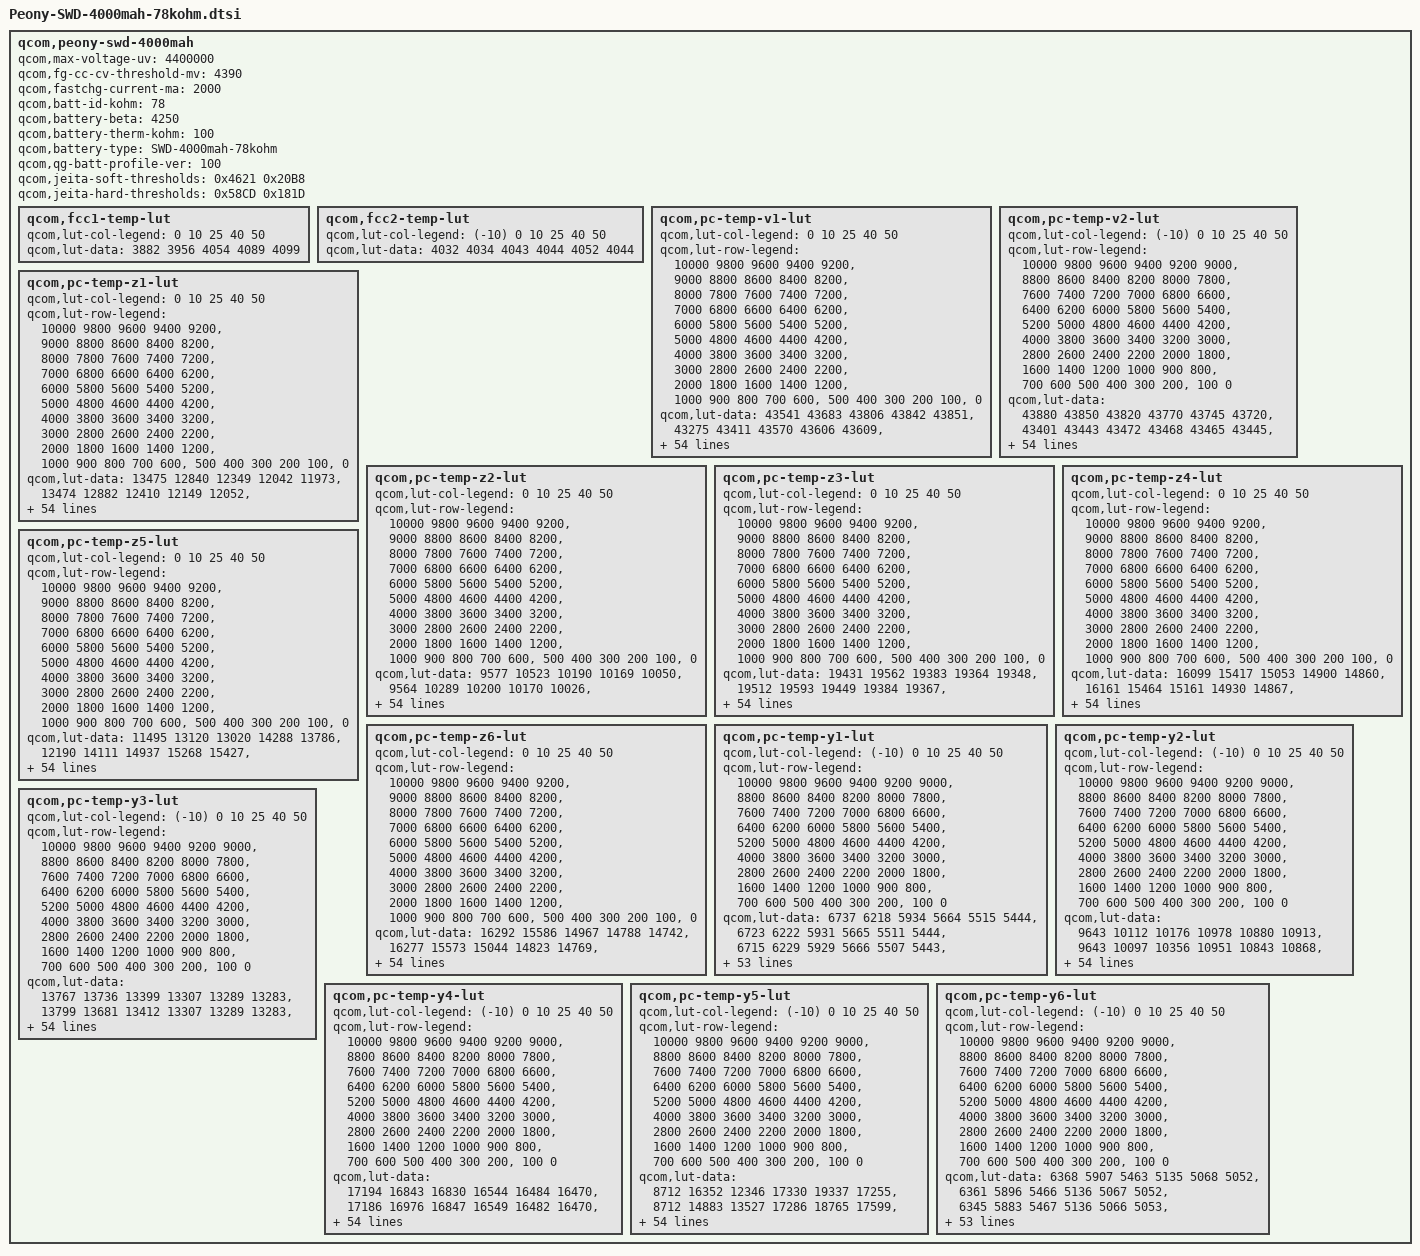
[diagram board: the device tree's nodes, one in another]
/* Copyright (c) 2018, The Linux Foundation. All rights reserved.
 * Copyright (C) 2021 XiaoMi, Inc.
 *
 * This program is free software; you can redistribute it and/or modify
 * it under the terms of the GNU General Public License version 2 and
 * only version 2 as published by the Free Software Foundation.
 *
 * This program is distributed in the hope that it will be useful,
 * but WITHOUT ANY WARRANTY; without even the implied warranty of
 * MERCHANTABILITY or FITNESS FOR A PARTICULAR PURPOSE.  See the
 * GNU General Public License for more details.
 */

qcom,peony-swd-4000mah {
	/* Peony-SWD-4000mah-78kohm_Master_2018.12.27 */
	qcom,max-voltage-uv = <4400000>;
	qcom,fg-cc-cv-threshold-mv = <4390>;
	qcom,fastchg-current-ma = <2000>;
	qcom,batt-id-kohm = <78>;
	qcom,battery-beta = <4250>;
	qcom,battery-therm-kohm = <100>;
	qcom,battery-type =
		"SWD-4000mah-78kohm";
	qcom,qg-batt-profile-ver = <100>;

/*	qcom,jeita-fcc-ranges = <0   50   400000
				 51  100  1200000
				 101 150  1950000
				 151 450  2000000
				 451 550  1000000
				 551 600  0>;
	qcom,jeita-fv-ranges =  <0   50   4400000
				 51  100  4400000
				 101 150  4400000
				 151 450  4400000
				 451 550  4100000
				 551 600  4100000>;*/

	/* COOL = 15 DegC, WARM = 45 DegC */
	qcom,jeita-soft-thresholds = <0x4621 0x20B8>;
	/* COLD = 0 DegC, HOT = 55 DegC */
	qcom,jeita-hard-thresholds = <0x58CD 0x181D>;

	qcom,fcc1-temp-lut {
		qcom,lut-col-legend = <0 10 25 40 50>;
		qcom,lut-data = <3882 3956 4054 4089 4099>;
	};

	qcom,fcc2-temp-lut {
		qcom,lut-col-legend = <(-10) 0 10 25 40 50>;
		qcom,lut-data = <4032 4034 4043 4044 4052 4044>;
	};

	qcom,pc-temp-v1-lut {
		qcom,lut-col-legend = <0 10 25 40 50>;
		qcom,lut-row-legend = <10000 9800 9600 9400 9200>,
			<9000 8800 8600 8400 8200>,
			<8000 7800 7600 7400 7200>,
			<7000 6800 6600 6400 6200>,
			<6000 5800 5600 5400 5200>,
			<5000 4800 4600 4400 4200>,
			<4000 3800 3600 3400 3200>,
			<3000 2800 2600 2400 2200>,
			<2000 1800 1600 1400 1200>,
			<1000 900 800 700 600>,
			<500 400 300 200 100>,
			<0>;
		qcom,lut-data = <43541 43683 43806 43842 43851>,
			<43275 43411 43570 43606 43609>,
			<43017 43151 43319 43369 43380>,
			<42767 42904 43068 43127 43146>,
			<42531 42666 42823 42887 42910>,
			<42307 42434 42582 42647 42670>,
			<42091 42209 42346 42409 42431>,
			<41878 41990 42113 42172 42195>,
			<41669 41772 41886 41936 41962>,
			<41475 41560 41658 41704 41730>,
			<41314 41370 41435 41475 41499>,
			<41148 41210 41236 41255 41274>,
			<40910 41031 41069 41051 41052>,
			<40586 40757 40881 40850 40838>,
			<40298 40426 40595 40622 40629>,
			<40083 40180 40278 40372 40428>,
			<39902 40000 40078 40163 40236>,
			<39765 39853 39947 40008 40056>,
			<39661 39741 39822 39868 39884>,
			<39562 39648 39693 39720 39725>,
			<39452 39520 39554 39571 39576>,
			<39338 39319 39360 39388 39396>,
			<39199 39104 39094 39129 39142>,
			<39007 38911 38883 38893 38902>,
			<38820 38729 38753 38753 38756>,
			<38686 38614 38649 38645 38645>,
			<38577 38552 38557 38541 38538>,
			<38500 38504 38478 38440 38433>,
			<38451 38451 38403 38349 38339>,
			<38412 38402 38327 38271 38259>,
			<38378 38356 38260 38203 38189>,
			<38348 38312 38206 38142 38124>,
			<38320 38272 38161 38088 38065>,
			<38293 38237 38122 38038 38008>,
			<38267 38207 38090 37995 37957>,
			<38240 38176 38058 37953 37907>,
			<38213 38148 38023 37908 37855>,
			<38179 38115 37985 37862 37801>,
			<38123 38060 37933 37803 37735>,
			<38038 37967 37851 37719 37645>,
			<37937 37859 37749 37617 37539>,
			<37800 37738 37631 37502 37421>,
			<37665 37598 37492 37368 37287>,
			<37545 37425 37329 37206 37129>,
			<37395 37276 37180 37069 36995>,
			<37284 37188 37083 36985 36921>,
			<37250 37170 37059 36957 36898>,
			<37219 37156 37038 36943 36880>,
			<37191 37134 37023 36925 36861>,
			<37147 37090 36984 36869 36799>,
			<36944 36871 36748 36601 36515>,
			<36497 36424 36310 36160 36074>,
			<35915 35839 35732 35575 35493>,
			<35123 35041 34936 34772 34695>,
			<33876 33779 33693 33517 33456>,
			<30000 30000 30000 30000 30000>;
	};

	qcom,pc-temp-v2-lut {
		qcom,lut-col-legend = <(-10) 0 10 25 40 50>;
		qcom,lut-row-legend = <10000 9800 9600 9400 9200 9000>,
			<8800 8600 8400 8200 8000 7800>,
			<7600 7400 7200 7000 6800 6600>,
			<6400 6200 6000 5800 5600 5400>,
			<5200 5000 4800 4600 4400 4200>,
			<4000 3800 3600 3400 3200 3000>,
			<2800 2600 2400 2200 2000 1800>,
			<1600 1400 1200 1000 900 800>,
			<700 600 500 400 300 200>,
			<100 0>;
		qcom,lut-data = <43880 43850 43820 43770 43745 43720>,
			<43401 43443 43472 43468 43465 43445>,
			<42991 43077 43154 43183 43197 43181>,
			<42666 42755 42868 42918 42939 42927>,
			<42411 42468 42614 42671 42692 42685>,
			<42152 42218 42366 42429 42450 42446>,
			<41794 42013 42117 42190 42209 42207>,
			<41476 41822 41872 41956 41972 41970>,
			<41393 41583 41619 41726 41740 41737>,
			<41373 41290 41357 41500 41512 41507>,
			<41338 41103 41150 41281 41287 41281>,
			<41194 41046 41020 41075 41065 41059>,
			<40942 40999 40895 40870 40846 40842>,
			<40577 40775 40671 40646 40635 40632>,
			<40009 40190 40326 40407 40428 40428>,
			<39606 39801 40045 40183 40231 40233>,
			<39431 39688 39863 39978 40044 40048>,
			<39291 39599 39704 39793 39866 39871>,
			<39088 39437 39542 39647 39703 39705>,
			<38839 39202 39386 39528 39551 39549>,
			<38644 38962 39210 39379 39377 39375>,
			<38508 38708 38992 39154 39159 39163>,
			<38401 38481 38775 38918 38942 38949>,
			<38321 38339 38594 38730 38756 38761>,
			<38258 38232 38434 38565 38587 38588>,
			<38201 38157 38292 38428 38448 38447>,
			<38148 38105 38157 38317 38335 38335>,
			<38097 38062 38052 38220 38237 38237>,
			<38047 38021 37989 38130 38148 38146>,
			<37998 37983 37945 38048 38069 38064>,
			<37948 37945 37906 37974 37998 37992>,
			<37897 37906 37874 37901 37934 37928>,
			<37845 37867 37842 37842 37873 37866>,
			<37793 37830 37812 37800 37810 37802>,
			<37742 37794 37782 37767 37748 37737>,
			<37686 37753 37746 37729 37681 37659>,
			<37626 37705 37705 37687 37609 37561>,
			<37560 37650 37656 37637 37535 37464>,
			<37486 37585 37593 37569 37461 37387>,
			<37405 37510 37517 37485 37384 37315>,
			<37320 37423 37424 37395 37301 37237>,
			<37227 37317 37306 37295 37209 37150>,
			<37143 37193 37170 37172 37088 37032>,
			<37070 37050 37018 37027 36945 36882>,
			<36999 36930 36897 36900 36832 36782>,
			<36924 36850 36817 36850 36796 36745>,
			<36878 36826 36784 36830 36784 36734>,
			<36834 36797 36762 36816 36768 36718>,
			<36769 36763 36719 36787 36736 36687>,
			<36652 36685 36627 36714 36640 36583>,
			<36411 36471 36416 36471 36313 36229>,
			<36002 36031 35965 35989 35797 35718>,
			<35397 35396 35314 35364 35135 35054>,
			<34515 34492 34421 34520 34259 34176>,
			<33021 33035 33028 33140 32844 32829>,
			<28646 28289 27976 28159 27708 28253>;
	};

	qcom,pc-temp-z1-lut {
		qcom,lut-col-legend = <0 10 25 40 50>;
		qcom,lut-row-legend = <10000 9800 9600 9400 9200>,
			<9000 8800 8600 8400 8200>,
			<8000 7800 7600 7400 7200>,
			<7000 6800 6600 6400 6200>,
			<6000 5800 5600 5400 5200>,
			<5000 4800 4600 4400 4200>,
			<4000 3800 3600 3400 3200>,
			<3000 2800 2600 2400 2200>,
			<2000 1800 1600 1400 1200>,
			<1000 900 800 700 600>,
			<500 400 300 200 100>,
			<0>;
		qcom,lut-data = <13475 12840 12349 12042 11973>,
			<13474 12882 12410 12149 12052>,
			<13506 12909 12422 12154 12061>,
			<13539 12923 12430 12155 12065>,
			<13545 12931 12425 12153 12066>,
			<13522 12928 12413 12147 12065>,
			<13501 12917 12406 12143 12065>,
			<13502 12904 12401 12141 12066>,
			<13511 12894 12399 12139 12068>,
			<13514 12884 12399 12139 12069>,
			<13501 12879 12399 12141 12070>,
			<13479 12878 12399 12142 12070>,
			<13457 12876 12401 12141 12069>,
			<13425 12859 12401 12140 12068>,
			<13396 12831 12389 12136 12069>,
			<13365 12822 12371 12127 12072>,
			<13337 12821 12368 12123 12074>,
			<13332 12820 12371 12125 12071>,
			<13336 12825 12375 12129 12069>,
			<13340 12836 12381 12132 12070>,
			<13340 12844 12388 12136 12072>,
			<13339 12850 12391 12139 12073>,
			<13342 12854 12397 12141 12074>,
			<13367 12855 12402 12143 12075>,
			<13389 12854 12409 12146 12079>,
			<13388 12855 12416 12151 12084>,
			<13378 12858 12418 12155 12088>,
			<13373 12862 12418 12160 12091>,
			<13382 12867 12419 12164 12093>,
			<13393 12872 12422 12169 12097>,
			<13399 12875 12427 12174 12101>,
			<13405 12874 12432 12179 12104>,
			<13409 12874 12436 12184 12107>,
			<13412 12879 12441 12189 12111>,
			<13417 12889 12447 12192 12115>,
			<13425 12900 12452 12196 12120>,
			<13444 12910 12455 12199 12124>,
			<13460 12921 12458 12204 12127>,
			<13462 12928 12462 12209 12131>,
			<13462 12935 12476 12215 12136>,
			<13467 12939 12488 12220 12141>,
			<13502 12933 12489 12225 12147>,
			<13521 12929 12487 12231 12153>,
			<13506 12955 12496 12237 12155>,
			<13533 12969 12504 12245 12158>,
			<13530 12961 12503 12250 12160>,
			<13569 12963 12502 12250 12161>,
			<13543 12961 12510 12248 12162>,
			<13506 12984 12506 12253 12163>,
			<13547 12960 12520 12260 12169>,
			<13537 12977 12522 12266 12178>,
			<13560 12985 12528 12277 12190>,
			<13587 13029 12549 12290 12201>,
			<13611 13039 12576 12311 12219>,
			<13611 13039 12576 12311 12219>,
			<13611 13039 12576 12311 12219>;
	};

	qcom,pc-temp-z2-lut {
		qcom,lut-col-legend = <0 10 25 40 50>;
		qcom,lut-row-legend = <10000 9800 9600 9400 9200>,
			<9000 8800 8600 8400 8200>,
			<8000 7800 7600 7400 7200>,
			<7000 6800 6600 6400 6200>,
			<6000 5800 5600 5400 5200>,
			<5000 4800 4600 4400 4200>,
			<4000 3800 3600 3400 3200>,
			<3000 2800 2600 2400 2200>,
			<2000 1800 1600 1400 1200>,
			<1000 900 800 700 600>,
			<500 400 300 200 100>,
			<0>;
		qcom,lut-data = <9577 10523 10190 10169 10050>,
			<9564 10289 10200 10170 10026>,
			<9701 10159 10222 10168 10025>,
			<9934 10147 10241 10174 9987>,
			<9993 10138 10229 10171 9975>,
			<9980 10126 10201 10157 9973>,
			<9965 10106 10210 10141 9970>,
			<9951 10087 10433 10122 9953>,
			<9937 10072 10630 10099 9927>,
			<9932 10060 10504 10069 9923>,
			<9937 10058 10230 10024 9931>,
			<9941 10064 10154 10003 9941>,
			<9938 10073 10160 10023 9954>,
			<9925 10091 10170 10060 9972>,
			<9916 10115 10192 10100 9984>,
			<9925 10126 10217 10153 9995>,
			<9942 10129 10214 10172 10002>,
			<9963 10133 10178 10103 10006>,
			<9994 10145 10157 10030 10010>,
			<10022 10168 10174 10035 10018>,
			<10042 10192 10210 10067 10033>,
			<10059 10221 10259 10122 10060>,
			<10073 10241 10336 10274 10173>,
			<10084 10239 10371 10393 10277>,
			<10093 10230 10331 10321 10254>,
			<10102 10226 10281 10168 10181>,
			<10111 10226 10282 10143 10156>,
			<10120 10227 10306 10243 10150>,
			<10133 10229 10318 10313 10140>,
			<10146 10232 10320 10259 10096>,
			<10157 10237 10322 10168 10024>,
			<10165 10252 10314 10135 9996>,
			<10174 10267 10295 10121 9979>,
			<10186 10274 10287 10116 9977>,
			<10200 10282 10293 10124 9998>,
			<10213 10288 10304 10142 10032>,
			<10226 10298 10324 10172 10070>,
			<10240 10313 10356 10226 10115>,
			<10255 10327 10380 10267 10155>,
			<10272 10344 10398 10296 10192>,
			<10288 10357 10409 10316 10216>,
			<10302 10364 10405 10324 10212>,
			<10344 10371 10395 10332 10200>,
			<10626 10386 10396 10340 10195>,
			<11070 10505 10420 10319 10188>,
			<11361 10998 10457 10268 10178>,
			<11441 17233 10431 10279 10187>,
			<11704 16563 10415 10274 10188>,
			<11722 12434 10426 10289 10231>,
			<11649 21137 10462 10358 10309>,
			<11112 17245 10476 10258 10163>,
			<10921 24263 10435 10166 10028>,
			<10420 17665 10374 10137 10016>,
			<10119 20353 10374 10116 9962>,
			<10119 20353 10374 10116 9962>,
			<10119 20353 10374 10116 9962>;
	};

	qcom,pc-temp-z3-lut {
		qcom,lut-col-legend = <0 10 25 40 50>;
		qcom,lut-row-legend = <10000 9800 9600 9400 9200>,
			<9000 8800 8600 8400 8200>,
			<8000 7800 7600 7400 7200>,
			<7000 6800 6600 6400 6200>,
			<6000 5800 5600 5400 5200>,
			<5000 4800 4600 4400 4200>,
			<4000 3800 3600 3400 3200>,
			<3000 2800 2600 2400 2200>,
			<2000 1800 1600 1400 1200>,
			<1000 900 800 700 600>,
			<500 400 300 200 100>,
			<0>;
		qcom,lut-data = <19431 19562 19383 19364 19348>,
			<19512 19593 19449 19384 19367>,
			<19628 19612 19476 19403 19381>,
			<19777 19626 19488 19416 19391>,
			<19822 19640 19488 19420 19398>,
			<19825 19642 19487 19421 19403>,
			<19825 19637 19488 19422 19406>,
			<19826 19632 19498 19423 19406>,
			<19828 19630 19507 19424 19405>,
			<19827 19629 19501 19423 19404>,
			<19799 19624 19487 19416 19403>,
			<19765 19607 19475 19411 19400>,
			<19772 19593 19463 19407 19399>,
			<19816 19597 19456 19405 19397>,
			<19842 19606 19461 19406 19394>,
			<19829 19608 19469 19412 19389>,
			<19801 19599 19469 19414 19386>,
			<19772 19585 19458 19404 19382>,
			<19734 19569 19447 19390 19378>,
			<19710 19550 19439 19382 19373>,
			<19705 19546 19432 19376 19367>,
			<19704 19562 19435 19376 19365>,
			<19706 19576 19449 19390 19375>,
			<19720 19576 19456 19402 19385>,
			<19734 19575 19447 19394 19384>,
			<19733 19572 19435 19377 19382>,
			<19728 19567 19437 19378 19384>,
			<19722 19562 19448 19413 19407>,
			<19716 19562 19460 19437 19425>,
			<19710 19563 19471 19434 19421>,
			<19702 19563 19479 19427 19410>,
			<19694 19564 19478 19421 19402>,
			<19686 19564 19471 19413 19395>,
			<19680 19563 19464 19406 19388>,
			<19673 19558 19456 19399 19380>,
			<19667 19554 19450 19393 19372>,
			<19660 19550 19445 19388 19368>,
			<19654 19545 19441 19384 19365>,
			<19648 19541 19438 19382 19364>,
			<19641 19537 19434 19381 19365>,
			<19635 19532 19431 19381 19366>,
			<19631 19526 19428 19381 19368>,
			<19601 19519 19425 19381 19370>,
			<19299 19513 19421 19382 19371>,
			<19259 19487 19411 19378 19370>,
			<19258 19457 19401 19362 19359>,
			<19258 19358 19393 19361 19348>,
			<19258 19259 19393 19349 19342>,
			<19258 19259 19384 19346 19337>,
			<19258 19256 19375 19342 19328>,
			<19258 19257 19377 19367 19359>,
			<19259 19256 19388 19368 19358>,
			<19260 19258 19373 19367 19358>,
			<19261 19256 19366 19370 19361>,
			<19261 19256 19366 19370 19361>,
			<19261 19256 19366 19370 19361>;
	};

	qcom,pc-temp-z4-lut {
		qcom,lut-col-legend = <0 10 25 40 50>;
		qcom,lut-row-legend = <10000 9800 9600 9400 9200>,
			<9000 8800 8600 8400 8200>,
			<8000 7800 7600 7400 7200>,
			<7000 6800 6600 6400 6200>,
			<6000 5800 5600 5400 5200>,
			<5000 4800 4600 4400 4200>,
			<4000 3800 3600 3400 3200>,
			<3000 2800 2600 2400 2200>,
			<2000 1800 1600 1400 1200>,
			<1000 900 800 700 600>,
			<500 400 300 200 100>,
			<0>;
		qcom,lut-data = <16099 15417 15053 14900 14860>,
			<16161 15464 15161 14930 14867>,
			<16010 15449 15104 14926 14876>,
			<15698 15341 15028 14891 14855>,
			<15483 15180 14972 14861 14835>,
			<15346 15074 14921 14834 14814>,
			<15237 15003 14873 14809 14794>,
			<15149 14948 14816 14786 14777>,
			<15076 14905 14777 14767 14761>,
			<15017 14870 14769 14755 14748>,
			<14966 14836 14769 14746 14736>,
			<14928 14800 14762 14738 14727>,
			<14908 14779 14742 14727 14721>,
			<14895 14786 14729 14719 14716>,
			<14886 14801 14747 14720 14712>,
			<14880 14805 14777 14728 14709>,
			<14873 14795 14775 14731 14706>,
			<14861 14779 14738 14715 14701>,
			<14836 14757 14711 14696 14695>,
			<14810 14731 14707 14692 14690>,
			<14786 14725 14705 14690 14686>,
			<14763 14753 14722 14695 14688>,
			<14760 14794 14799 14756 14750>,
			<14797 14840 14848 14815 14809>,
			<14843 14892 14859 14826 14809>,
			<14869 14908 14865 14831 14801>,
			<14890 14891 14858 14825 14786>,
			<14897 14867 14826 14775 14749>,
			<14884 14848 14799 14734 14720>,
			<14865 14829 14779 14727 14714>,
			<14848 14814 14765 14723 14711>,
			<14831 14801 14762 14720 14708>,
			<14816 14790 14761 14718 14704>,
			<14802 14782 14759 14717 14702>,
			<14790 14775 14756 14716 14702>,
			<14778 14769 14754 14716 14703>,
			<14766 14762 14752 14716 14703>,
			<14757 14756 14750 14715 14703>,
			<14753 14756 14749 14715 14704>,
			<14750 14757 14749 14718 14708>,
			<14747 14758 14748 14722 14713>,
			<14740 14748 14741 14716 14709>,
			<14758 14734 14728 14704 14700>,
			<15036 14725 14720 14703 14701>,
			<14999 14700 14700 14695 14695>,
			<14966 14689 14676 14673 14668>,
			<14956 14782 14672 14665 14666>,
			<14948 14880 14660 14659 14655>,
			<14943 14870 14655 14641 14636>,
			<14937 14866 14658 14640 14636>,
			<14941 14878 14674 14650 14653>,
			<14964 14888 14671 14658 14665>,
			<14972 14892 14686 14662 14669>,
			<14986 14896 14695 14660 14668>,
			<14986 14896 14695 14660 14668>,
			<14986 14896 14695 14660 14668>;
	};

	qcom,pc-temp-z5-lut {
		qcom,lut-col-legend = <0 10 25 40 50>;
		qcom,lut-row-legend = <10000 9800 9600 9400 9200>,
			<9000 8800 8600 8400 8200>,
			<8000 7800 7600 7400 7200>,
			<7000 6800 6600 6400 6200>,
			<6000 5800 5600 5400 5200>,
			<5000 4800 4600 4400 4200>,
			<4000 3800 3600 3400 3200>,
			<3000 2800 2600 2400 2200>,
			<2000 1800 1600 1400 1200>,
			<1000 900 800 700 600>,
			<500 400 300 200 100>,
			<0>;
		qcom,lut-data = <11495 13120 13020 14288 13786>,
			<12190 14111 14937 15268 15427>,
			<13179 15039 16021 16292 16148>,
			<14384 15959 16790 17248 16928>,
			<15196 16882 17257 17775 17710>,
			<15678 17603 17589 18034 18512>,
			<16153 18123 18250 18322 19177>,
			<17006 18721 20191 18957 19565>,
			<18126 19823 21863 19684 19867>,
			<18545 21119 21946 19966 20329>,
			<18232 21727 21515 20075 21064>,
			<17866 21932 21448 20214 21839>,
			<19334 22218 21618 20602 22623>,
			<25201 24649 21904 21233 23325>,
			<28678 28936 23283 22834 23724>,
			<27584 29933 25139 26493 24031>,
			<25502 27440 25267 27991 24188>,
			<23856 25095 24277 25577 24556>,
			<22203 24784 23706 23019 24944>,
			<21277 24876 25214 22998 25055>,
			<22402 26225 27919 23538 25366>,
			<25625 37300 30184 24383 25738>,
			<30311 47505 32654 26459 26438>,
			<41671 45742 33636 28034 26988>,
			<51254 39333 28193 24758 24553>,
			<50686 34396 21396 18034 18940>,
			<46843 30667 20788 16923 17836>,
			<43538 28317 21536 21298 22643>,
			<41281 28282 22779 25261 26552>,
			<39415 28759 27028 26628 26596>,
			<38010 29512 31676 27572 26262>,
			<36813 31568 33321 28480 26418>,
			<36188 33992 34301 29376 27193>,
			<36080 35534 34592 29859 27646>,
			<36162 36861 34545 29986 27527>,
			<36465 37717 34443 29997 27309>,
			<37251 38347 34260 29884 27142>,
			<38086 38782 33848 29589 26979>,
			<38749 38743 33169 29128 26718>,
			<39344 38319 31278 27787 25903>,
			<39487 37625 29343 26448 25163>,
			<39092 35306 28396 26034 25348>,
			<36661 33400 27669 25802 26031>,
			<14225 33689 26578 26294 26820>,
			<11496 34738 27103 25856 27421>,
			<11532 30642 28586 22972 24585>,
			<11485 22255 25771 23050 20234>,
			<11480 11508 27864 20983 20450>,
			<11465 11452 26094 23902 23981>,
			<11464 11446 22044 22558 21131>,
			<11507 11433 20588 26361 26006>,
			<11418 11366 22138 22357 21084>,
			<11341 11306 17064 20297 19013>,
			<11237 11214 15793 19604 17686>,
			<11237 11214 15793 19604 17686>,
			<11237 11214 15793 19604 17686>;
	};

	qcom,pc-temp-z6-lut {
		qcom,lut-col-legend = <0 10 25 40 50>;
		qcom,lut-row-legend = <10000 9800 9600 9400 9200>,
			<9000 8800 8600 8400 8200>,
			<8000 7800 7600 7400 7200>,
			<7000 6800 6600 6400 6200>,
			<6000 5800 5600 5400 5200>,
			<5000 4800 4600 4400 4200>,
			<4000 3800 3600 3400 3200>,
			<3000 2800 2600 2400 2200>,
			<2000 1800 1600 1400 1200>,
			<1000 900 800 700 600>,
			<500 400 300 200 100>,
			<0>;
		qcom,lut-data = <16292 15586 14967 14788 14742>,
			<16277 15573 15044 14823 14769>,
			<16208 15550 15026 14827 14777>,
			<16078 15488 15000 14821 14775>,
			<15966 15394 14973 14813 14773>,
			<15871 15326 14944 14801 14768>,
			<15788 15274 14920 14789 14761>,
			<15724 15232 14901 14780 14754>,
			<15671 15200 14885 14772 14747>,
			<15620 15173 14874 14764 14741>,
			<15560 15143 14864 14757 14735>,
			<15511 15107 14853 14751 14729>,
			<15490 15084 14836 14744 14725>,
			<15479 15080 14827 14739 14722>,
			<15467 15079 14834 14740 14718>,
			<15445 15076 14846 14744 14715>,
			<15417 15066 14845 14745 14711>,
			<15388 15052 14824 14733 14706>,
			<15355 15037 14809 14718 14701>,
			<15332 15020 14804 14712 14696>,
			<15324 15017 14802 14709 14691>,
			<15319 15039 14812 14711 14692>,
			<15319 15067 14855 14746 14724>,
			<15345 15090 14878 14777 14755>,
			<15374 15113 14878 14777 14755>,
			<15387 15119 14879 14773 14751>,
			<15396 15112 14877 14771 14748>,
			<15399 15102 14871 14769 14746>,
			<15393 15094 14868 14766 14743>,
			<15382 15088 14867 14763 14738>,
			<15373 15083 14866 14758 14732>,
			<15363 15079 14865 14754 14727>,
			<15354 15076 14861 14750 14722>,
			<15347 15073 14858 14746 14718>,
			<15341 15069 14854 14742 14714>,
			<15336 15067 14851 14739 14710>,
			<15332 15066 14849 14737 14708>,
			<15330 15064 14848 14735 14707>,
			<15332 15066 14848 14735 14706>,
			<15336 15070 14848 14737 14709>,
			<15341 15072 14848 14738 14712>,
			<15348 15068 14846 14737 14712>,
			<15350 15065 14842 14733 14710>,
			<15337 15067 14840 14734 14712>,
			<15317 15056 14832 14730 14709>,
			<15305 15044 14820 14713 14692>,
			<15303 15034 14815 14709 14685>,
			<15301 15026 14810 14701 14677>,
			<15299 15024 14804 14692 14667>,
			<15303 15026 14804 14690 14663>,
			<15312 15038 14816 14710 14688>,
			<15333 15051 14825 14717 14696>,
			<15350 15063 14829 14722 14701>,
			<15378 15081 14838 14727 14706>,
			<15378 15081 14838 14727 14706>,
			<15378 15081 14838 14727 14706>;
	};

	qcom,pc-temp-y1-lut {
		qcom,lut-col-legend = <(-10) 0 10 25 40 50>;
		qcom,lut-row-legend = <10000 9800 9600 9400 9200 9000>,
			<8800 8600 8400 8200 8000 7800>,
			<7600 7400 7200 7000 6800 6600>,
			<6400 6200 6000 5800 5600 5400>,
			<5200 5000 4800 4600 4400 4200>,
			<4000 3800 3600 3400 3200 3000>,
			<2800 2600 2400 2200 2000 1800>,
			<1600 1400 1200 1000 900 800>,
			<700 600 500 400 300 200>,
			<100 0>;
		qcom,lut-data = <6737 6218 5934 5664 5515 5444>,
			<6723 6222 5931 5665 5511 5444>,
			<6715 6229 5929 5666 5507 5443>,
			<6710 6235 5928 5666 5503 5442>,
			<6708 6240 5928 5667 5500 5441>,
			<6707 6242 5928 5667 5497 5439>,
			<6719 6247 5936 5667 5495 5438>,
			<6736 6253 5946 5668 5493 5436>,
			<6740 6250 5945 5666 5492 5435>,
			<6747 6242 5938 5661 5490 5434>,
			<6753 6236 5934 5657 5489 5433>,
			<6752 6242 5933 5656 5487 5432>,
			<6749 6250 5933 5655 5486 5432>,
			<6746 6250 5938 5654 5483 5431>,
			<6735 6249 5950 5652 5479 5431>,
			<6732 6251 5956 5651 5477 5431>,
			<6757 6257 5955 5657 5484 5431>,
			<6786 6264 5953 5665 5491 5431>,
			<6782 6266 5954 5664 5491 5431>,
			<6757 6263 5959 5660 5488 5432>,
			<6744 6262 5961 5658 5487 5433>,
			<6740 6268 5960 5663 5488 5435>,
			<6739 6275 5959 5669 5488 5437>,
			<6741 6276 5958 5672 5491 5438>,
			<6748 6276 5961 5676 5497 5440>,
			<6751 6277 5961 5680 5500 5441>,
			<6742 6278 5959 5685 5500 5443>,
			<6733 6278 5957 5690 5501 5445>,
			<6728 6270 5957 5691 5506 5448>,
			<6721 6255 5959 5693 5514 5452>,
			<6720 6250 5960 5695 5519 5456>,
			<6731 6254 5959 5701 5522 5462>,
			<6741 6257 5957 5707 5525 5466>,
			<6746 6259 5956 5711 5528 5468>,
			<6756 6266 5956 5714 5532 5469>,
			<6760 6268 5956 5715 5535 5471>,
			<6749 6261 5960 5716 5538 5473>,
			<6738 6254 5964 5717 5541 5474>,
			<6732 6257 5963 5719 5544 5476>,
			<6720 6265 5961 5721 5547 5477>,
			<6717 6267 5960 5723 5549 5479>,
			<6718 6256 5960 5729 5551 5483>,
			<6726 6255 5962 5737 5554 5486>,
			<6751 6270 5973 5747 5559 5489>,
			<6782 6277 5990 5753 5569 5498>,
			<6797 6304 5998 5756 5575 5499>,
			<6836 6318 5988 5761 5575 5499>,
			<6816 6303 5992 5760 5573 5498>,
			<6850 6305 6020 5755 5572 5498>,
			<6829 6323 6024 5756 5570 5497>,
			<6824 6332 6015 5760 5576 5501>,
			<6864 6337 6039 5772 5586 5509>,
			<6953 6357 6044 5791 5599 5518>,
			<6976 6403 6084 5801 5619 5530>,
			<6976 6403 6084 5801 5619 5530>,
			<6976 6403 6084 5801 5619 5530>;
	};

	qcom,pc-temp-y2-lut {
		qcom,lut-col-legend = <(-10) 0 10 25 40 50>;
		qcom,lut-row-legend = <10000 9800 9600 9400 9200 9000>,
			<8800 8600 8400 8200 8000 7800>,
			<7600 7400 7200 7000 6800 6600>,
			<6400 6200 6000 5800 5600 5400>,
			<5200 5000 4800 4600 4400 4200>,
			<4000 3800 3600 3400 3200 3000>,
			<2800 2600 2400 2200 2000 1800>,
			<1600 1400 1200 1000 900 800>,
			<700 600 500 400 300 200>,
			<100 0>;
		qcom,lut-data = <9643 10112 10176 10978 10880 10913>,
			<9643 10097 10356 10951 10843 10868>,
			<9842 10090 10474 10926 10803 10813>,
			<10047 10090 10544 10903 10765 10758>,
			<10129 10096 10577 10881 10733 10710>,
			<10143 10107 10585 10862 10712 10680>,
			<9966 10208 10534 10844 10698 10662>,
			<9715 10341 10464 10828 10688 10648>,
			<9675 10346 10473 10817 10686 10640>,
			<9675 10277 10556 10809 10692 10635>,
			<9675 10240 10609 10795 10693 10631>,
			<9676 10296 10619 10742 10669 10622>,
			<9677 10402 10626 10686 10642 10610>,
			<9676 10512 10676 10704 10643 10600>,
			<9671 10644 10812 10796 10660 10587>,
			<9668 10796 10903 10866 10678 10583>,
			<9668 11029 10931 10896 10721 10597>,
			<9667 11222 10956 10925 10778 10623>,
			<9667 10978 11028 10991 10825 10658>,
			<9667 10108 11152 11096 10873 10715>,
			<9666 9701 11199 11135 10918 10776>,
			<9666 9690 11192 11125 10968 10859>,
			<9665 9685 11177 11114 10999 10921>,
			<9665 9682 11128 11114 10982 10920>,
			<9664 9681 11010 11116 10939 10897>,
			<9664 9679 10863 11122 10928 10885>,
			<9664 9677 10619 11143 10952 10878>,
			<9664 9674 10440 11171 10984 10873>,
			<9664 9671 10546 11202 11025 10898>,
			<9663 9669 10806 11240 11081 10961>,
			<9663 9668 10862 11249 11114 11014>,
			<9663 9666 10578 11225 11149 11071>,
			<9662 9665 10237 11195 11170 11108>,
			<9662 9664 10009 11178 11173 11098>,
			<9662 9663 9818 11161 11174 11068>,
			<9662 9663 9740 11138 11161 11038>,
			<9662 9662 9708 11100 11119 10996>,
			<9662 9661 9690 11057 11076 10953>,
			<9662 9661 9682 11018 11046 10909>,
			<9661 9661 9677 10978 11020 10870>,
			<9661 9660 9673 10939 11006 10865>,
			<9661 9660 9670 10902 10996 10880>,
			<9661 9660 9667 10850 10966 10877>,
			<9660 9659 9665 10782 10900 10834>,
			<9660 9659 9663 10714 10830 10730>,
			<9659 9659 9663 10740 10795 10661>,
			<9659 9659 9662 10679 10769 10648>,
			<9659 9658 9661 10699 10801 10716>,
			<9658 9658 9660 10677 10830 10736>,
			<9657 9658 9660 10659 10831 10734>,
			<9657 9657 9659 10628 10790 10671>,
			<9656 9656 9658 10562 10721 10616>,
			<9654 9656 9657 10488 10649 10542>,
			<9652 9655 9656 10450 10665 10487>,
			<9652 9655 9656 10450 10665 10487>,
			<9652 9655 9656 10450 10665 10487>;
	};

	qcom,pc-temp-y3-lut {
		qcom,lut-col-legend = <(-10) 0 10 25 40 50>;
		qcom,lut-row-legend = <10000 9800 9600 9400 9200 9000>,
			<8800 8600 8400 8200 8000 7800>,
			<7600 7400 7200 7000 6800 6600>,
			<6400 6200 6000 5800 5600 5400>,
			<5200 5000 4800 4600 4400 4200>,
			<4000 3800 3600 3400 3200 3000>,
			<2800 2600 2400 2200 2000 1800>,
			<1600 1400 1200 1000 900 800>,
			<700 600 500 400 300 200>,
			<100 0>;
		qcom,lut-data = <13767 13736 13399 13307 13289 13283>,
			<13799 13681 13412 13307 13289 13283>,
			<13807 13642 13420 13308 13289 13284>,
			<13796 13618 13423 13309 13289 13284>,
			<13773 13605 13425 13310 13289 13285>,
			<13740 13601 13425 13311 13289 13285>,
			<13682 13616 13418 13312 13289 13286>,
			<13620 13638 13409 13313 13289 13287>,
			<13602 13609 13415 13314 13289 13287>,
			<13594 13472 13447 13316 13292 13288>,
			<13592 13397 13464 13317 13293 13288>,
			<13607 13422 13418 13319 13293 13289>,
			<13626 13455 13361 13320 13292 13290>,
			<13615 13454 13364 13320 13293 13290>,
			<13567 13431 13397 13319 13296 13290>,
			<13543 13414 13412 13319 13297 13291>,
			<13560 13406 13394 13317 13299 13293>,
			<13582 13402 13371 13315 13300 13296>,
			<13583 13405 13365 13315 13300 13296>,
			<13579 13418 13362 13314 13298 13295>,
			<13577 13424 13358 13312 13297 13294>,
			<13576 13417 13348 13309 13294 13292>,
			<13575 13404 13337 13305 13291 13289>,
			<13581 13388 13330 13302 13289 13286>,
			<13602 13367 13326 13299 13286 13282>,
			<13625 13360 13316 13298 13285 13281>,
			<13648 13381 13286 13297 13284 13281>,
			<13673 13411 13261 13297 13284 13281>,
			<13697 13436 13273 13296 13284 13281>,
			<13721 13460 13304 13295 13284 13281>,
			<13747 13486 13315 13295 13284 13281>,
			<13777 13514 13315 13294 13283 13280>,
			<13808 13544 13315 13293 13283 13280>,
			<13839 13578 13322 13294 13283 13280>,
			<13868 13618 13337 13295 13284 13282>,
			<13898 13656 13350 13297 13284 13282>,
			<13929 13695 13359 13298 13285 13281>,
			<13960 13732 13369 13300 13285 13280>,
			<13992 13768 13386 13300 13286 13281>,
			<14024 13802 13410 13300 13287 13283>,
			<14057 13834 13437 13301 13288 13285>,
			<14089 13862 13469 13305 13289 13286>,
			<14129 13892 13510 13306 13289 13286>,
			<14182 13927 13560 13307 13288 13283>,
			<14251 13969 13614 13309 13287 13284>,
			<14273 13973 13602 13311 13292 13288>,
			<14327 14025 13646 13313 13295 13291>,
			<14400 14066 13709 13320 13299 13293>,
			<14474 14132 13758 13325 13301 13295>,
			<14561 14189 13819 13331 13301 13294>,
			<14653 14244 13871 13332 13297 13290>,
			<14793 14318 13937 13333 13299 13292>,
			<15261 14461 14072 13341 13305 13297>,
			<16342 14686 14250 13356 13316 13308>,
			<16342 14686 14250 13356 13316 13308>,
			<16342 14686 14250 13356 13316 13308>;
	};

	qcom,pc-temp-y4-lut {
		qcom,lut-col-legend = <(-10) 0 10 25 40 50>;
		qcom,lut-row-legend = <10000 9800 9600 9400 9200 9000>,
			<8800 8600 8400 8200 8000 7800>,
			<7600 7400 7200 7000 6800 6600>,
			<6400 6200 6000 5800 5600 5400>,
			<5200 5000 4800 4600 4400 4200>,
			<4000 3800 3600 3400 3200 3000>,
			<2800 2600 2400 2200 2000 1800>,
			<1600 1400 1200 1000 900 800>,
			<700 600 500 400 300 200>,
			<100 0>;
		qcom,lut-data = <17194 16843 16830 16544 16484 16470>,
			<17186 16976 16847 16549 16482 16470>,
			<17181 17066 16873 16552 16480 16470>,
			<17179 17122 16901 16554 16479 16469>,
			<17178 17150 16923 16554 16478 16469>,
			<17178 17158 16932 16554 16478 16468>,
			<17261 17121 16931 16552 16479 16467>,
			<17419 17070 16928 16549 16480 16466>,
			<17568 17112 16902 16549 16480 16467>,
			<17737 17334 16812 16549 16480 16468>,
			<17811 17494 16768 16550 16480 16469>,
			<17746 17550 16957 16550 16483 16470>,
			<17612 17583 17192 16551 16487 16472>,
			<17421 17487 17150 16555 16492 16475>,
			<17122 17114 16909 16568 16497 16480>,
			<16953 16928 16797 16581 16503 16484>,
			<16917 16972 16842 16594 16511 16488>,
			<16891 17025 16891 16609 16521 16492>,
			<16833 17013 16894 16638 16540 16506>,
			<16744 16940 16886 16681 16569 16532>,
			<16704 16855 16871 16695 16577 16542>,
			<16701 16732 16806 16647 16559 16533>,
			<16700 16634 16725 16584 16533 16519>,
			<16700 16629 16665 16547 16507 16499>,
			<16700 16636 16613 16517 16480 16475>,
			<16701 16639 16598 16505 16473 16467>,
			<16697 16629 16609 16502 16472 16467>,
			<16694 16618 16619 16501 16473 16468>,
			<16696 16619 16595 16499 16475 16470>,
			<16704 16626 16540 16498 16482 16476>,
			<16711 16634 16525 16496 16488 16483>,
			<16718 16644 16549 16488 16498 16494>,
			<16724 16655 16580 16482 16503 16502>,
			<16729 16664 16603 16486 16501 16502>,
			<16734 16673 16624 16496 16496 16502>,
			<16738 16684 16645 16505 16490 16500>,
			<16743 16699 16667 16513 16480 16480>,
			<16746 16709 16682 16520 16474 16465>,
			<16743 16711 16689 16525 16475 16469>,
			<16734 16711 16694 16529 16479 16476>,
			<16728 16710 16694 16536 16485 16486>,
			<16724 16704 16692 16549 16495 16497>,
			<16724 16692 16686 16559 16493 16493>,
			<16738 16668 16674 16565 16481 16467>,
			<16757 16654 16667 16564 16474 16458>,
			<16748 16646 16661 16547 16482 16477>,
			<16767 16656 16670 16564 16500 16506>,
			<16790 16680 16692 16583 16529 16539>,
			<16819 16707 16722 16612 16565 16572>,
			<16834 16744 16757 16642 16574 16572>,
			<16828 16752 16785 16630 16515 16492>,
			<16812 16743 16763 16612 16505 16487>,
			<16894 16730 16754 16638 16524 16495>,
			<17187 16762 16764 16682 16583 16542>,
			<17187 16762 16764 16682 16583 16542>,
			<17187 16762 16764 16682 16583 16542>;
	};

	qcom,pc-temp-y5-lut {
		qcom,lut-col-legend = <(-10) 0 10 25 40 50>;
		qcom,lut-row-legend = <10000 9800 9600 9400 9200 9000>,
			<8800 8600 8400 8200 8000 7800>,
			<7600 7400 7200 7000 6800 6600>,
			<6400 6200 6000 5800 5600 5400>,
			<5200 5000 4800 4600 4400 4200>,
			<4000 3800 3600 3400 3200 3000>,
			<2800 2600 2400 2200 2000 1800>,
			<1600 1400 1200 1000 900 800>,
			<700 600 500 400 300 200>,
			<100 0>;
		qcom,lut-data = <8712 16352 12346 17330 19337 17255>,
			<8712 14883 13527 17286 18765 17599>,
			<12113 14238 14722 17252 18217 17822>,
			<15561 14241 15769 17230 17696 17950>,
			<17272 14716 16504 17217 17204 18007>,
			<17707 15494 16763 17215 16745 18020>,
			<15398 18208 16544 17231 16261 17950>,
			<12134 21407 16180 17250 15857 17815>,
			<11980 20583 16484 17230 15833 17655>,
			<13866 15058 18517 17100 16315 17363>,
			<16320 12060 19623 16881 16502 17032>,
			<20260 15548 17230 16006 15791 16673>,
			<23923 20081 14218 15064 14990 16289>,
			<22804 19918 15487 15080 15004 15881>,
			<16854 17133 20904 15485 15321 15430>,
			<13870 15784 23354 15657 15486 15270>,
			<16267 18170 20651 15082 15211 15620>,
			<19197 21152 17590 14424 14898 16013>,
			<19012 21736 18078 14612 14778 15770>,
			<17040 21928 20477 15584 14513 14952>,
			<15226 21954 21958 16871 14647 14744>,
			<13673 20856 22418 19217 17041 17190>,
			<12598 19012 22819 21244 19496 19668>,
			<12503 16688 23639 21634 20067 19672>,
			<12497 13447 24739 21811 20374 19214>,
			<12504 12292 24648 21948 20331 18726>,
			<12726 12697 18222 22054 19158 18142>,
			<13013 13196 12204 22160 18070 17600>,
			<13149 13406 12952 22511 17869 17132>,
			<13242 13544 15269 23147 17766 16642>,
			<13328 13614 15908 23276 17819 16525>,
			<13401 13640 14938 22531 18228 16464>,
			<13491 13670 14110 21653 18693 16512>,
			<13697 13947 14164 21119 19457 17850>,
			<14026 14550 14341 20642 20558 20244>,
			<14238 14831 14398 20129 21022 20806>,
			<14359 14883 14403 19602 21325 20270>,
			<14445 14898 14464 18989 21376 19865>,
			<14512 14992 14679 17997 20889 20170>,
			<14557 15182 14925 16897 20233 20705>,
			<14458 15222 14939 16497 19844 20811>,
			<13862 15034 14663 16380 19335 20695>,
			<13482 14841 14534 16098 19128 20142>,
			<13330 14610 14411 15685 18637 18765>,
			<13299 14359 14795 15919 16780 18532>,
			<13530 13859 14697 16896 17305 16631>,
			<13338 14157 14502 16117 17087 16071>,
			<13658 13750 14781 16469 16824 15500>,
			<13861 14100 14709 16345 16367 15178>,
			<14369 14398 15158 16434 16404 15216>,
			<14321 14611 15966 16996 17508 16555>,
			<14143 14142 15481 17787 18887 17225>,
			<12952 14318 14658 18010 19569 18042>,
			<11536 13799 14568 19227 23452 24162>,
			<11536 13799 14568 19227 23452 24162>,
			<11536 13799 14568 19227 23452 24162>;
	};

	qcom,pc-temp-y6-lut {
		qcom,lut-col-legend = <(-10) 0 10 25 40 50>;
		qcom,lut-row-legend = <10000 9800 9600 9400 9200 9000>,
			<8800 8600 8400 8200 8000 7800>,
			<7600 7400 7200 7000 6800 6600>,
			<6400 6200 6000 5800 5600 5400>,
			<5200 5000 4800 4600 4400 4200>,
			<4000 3800 3600 3400 3200 3000>,
			<2800 2600 2400 2200 2000 1800>,
			<1600 1400 1200 1000 900 800>,
			<700 600 500 400 300 200>,
			<100 0>;
		qcom,lut-data = <6368 5907 5463 5135 5068 5052>,
			<6361 5896 5466 5136 5067 5052>,
			<6345 5883 5467 5136 5066 5053>,
			<6322 5869 5467 5136 5066 5053>,
			<6294 5858 5466 5136 5065 5053>,
			<6261 5851 5464 5136 5065 5054>,
			<6211 5849 5457 5135 5065 5054>,
			<6164 5847 5445 5134 5065 5054>,
			<6167 5838 5436 5134 5066 5054>,
			<6210 5813 5425 5134 5067 5055>,
			<6233 5800 5420 5134 5068 5056>,
			<6223 5833 5442 5134 5068 5056>,
			<6201 5876 5468 5135 5069 5057>,
			<6149 5852 5458 5137 5071 5058>,
			<6034 5745 5415 5139 5073 5060>,
			<5980 5691 5395 5142 5076 5062>,
			<5983 5708 5396 5145 5080 5064>,
			<5988 5728 5397 5150 5084 5067>,
			<5981 5725 5397 5157 5090 5072>,
			<5957 5703 5395 5168 5096 5078>,
			<5946 5679 5390 5171 5098 5080>,
			<5948 5648 5368 5155 5090 5076>,
			<5952 5624 5341 5135 5080 5069>,
			<5960 5624 5326 5123 5071 5061>,
			<5976 5629 5315 5113 5062 5052>,
			<5993 5636 5307 5111 5059 5049>,
			<6009 5655 5301 5111 5058 5049>,
			<6027 5680 5297 5111 5058 5049>,
			<6046 5705 5303 5111 5059 5050>,
			<6067 5734 5319 5112 5062 5052>,
			<6090 5763 5337 5112 5064 5054>,
			<6115 5793 5359 5112 5067 5057>,
			<6141 5824 5384 5111 5069 5059>,
			<6167 5859 5411 5114 5069 5061>,
			<6193 5895 5442 5120 5069 5062>,
			<6219 5932 5474 5126 5068 5061>,
			<6245 5968 5509 5132 5066 5055>,
			<6270 6003 5546 5138 5065 5051>,
			<6295 6035 5585 5143 5066 5052>,
			<6319 6065 5626 5149 5068 5056>,
			<6344 6092 5667 5157 5071 5061>,
			<6371 6114 5707 5169 5076 5065>,
			<6408 6136 5752 5181 5076 5064>,
			<6461 6161 5804 5193 5073 5055>,
			<6530 6196 5853 5203 5072 5055>,
			<6555 6202 5844 5197 5079 5063>,
			<6606 6247 5888 5209 5087 5074>,
			<6671 6288 5946 5227 5097 5085>,
			<6746 6349 6000 5245 5108 5095>,
			<6825 6408 6065 5261 5110 5094>,
			<6910 6460 6125 5263 5092 5069>,
			<7032 6524 6174 5276 5092 5070>,
			<7475 6648 6291 5319 5105 5078>,
			<8465 6861 6452 5378 5134 5102>,
			<8465 6861 6452 5378 5134 5102>,
			<8465 6861 6452 5378 5134 5102>;
	};
};
